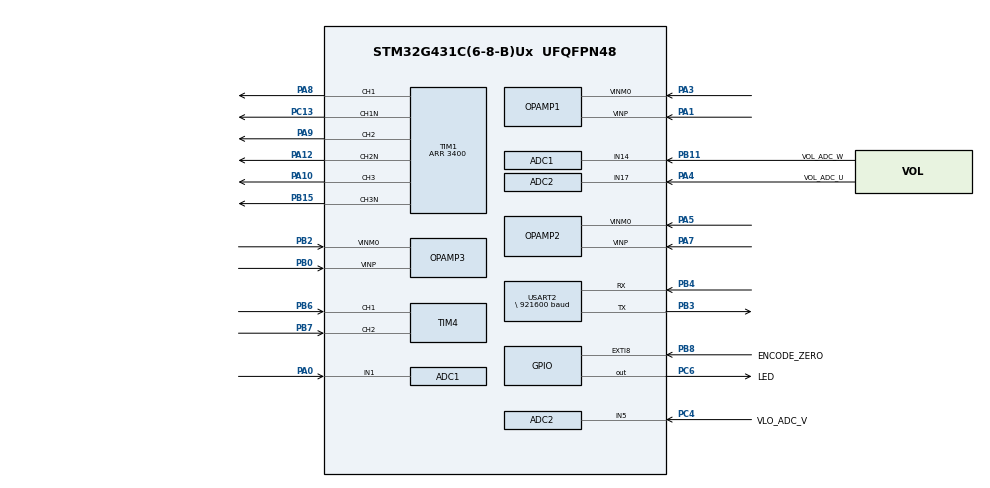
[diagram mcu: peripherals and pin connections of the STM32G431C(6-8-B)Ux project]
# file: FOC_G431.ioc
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ADC1.Channel-0\#ChannelRegularConversion=ADC_CHANNEL_VOPAMP1
ADC1.Channel-2\#ChannelRegularConversion=ADC_CHANNEL_1
ADC1.Channel-3\#ChannelRegularConversion=ADC_CHANNEL_14
ADC1.DMAAccessModeView=ENABLE
ADC1.DMAContinuousRequests=ENABLE
ADC1.EnableInjectedConversion=DISABLE
ADC1.ExternalTrigConv=ADC_EXTERNALTRIG_T1_TRGO2
ADC1.Mode=ADC_DUALMODE_REGSIMULT
ADC1.NbrOfConversion=3
ADC1.NbrOfConversionFlag=1
ADC1.OffsetNumber-0\#ChannelRegularConversion=ADC_OFFSET_NONE
ADC1.OffsetNumber-2\#ChannelRegularConversion=ADC_OFFSET_NONE
ADC1.OffsetNumber-3\#ChannelRegularConversion=ADC_OFFSET_NONE
ADC1.Rank-0\#ChannelRegularConversion=1
ADC1.Rank-2\#ChannelRegularConversion=2
ADC1.Rank-3\#ChannelRegularConversion=3
ADC1.SamplingTime-0\#ChannelRegularConversion=ADC_SAMPLETIME_12CYCLES_5
ADC1.SamplingTime-2\#ChannelRegularConversion=ADC_SAMPLETIME_12CYCLES_5
ADC1.SamplingTime-3\#ChannelRegularConversion=ADC_SAMPLETIME_12CYCLES_5
ADC1.master=1
ADC2.Channel-1\#ChannelRegularConversion=ADC_CHANNEL_VOPAMP2
ADC2.Channel-4\#ChannelRegularConversion=ADC_CHANNEL_5
ADC2.Channel-5\#ChannelRegularConversion=ADC_CHANNEL_17
ADC2.DMAAccessModeView=ENABLE
ADC2.EnableInjectedConversion=DISABLE
ADC2.Mode=ADC_DUALMODE_REGSIMULT
ADC2.NbrOfConversion=3
ADC2.NbrOfConversionFlag=1
ADC2.OffsetNumber-1\#ChannelRegularConversion=ADC_OFFSET_NONE
ADC2.OffsetNumber-4\#ChannelRegularConversion=ADC_OFFSET_NONE
ADC2.OffsetNumber-5\#ChannelRegularConversion=ADC_OFFSET_NONE
ADC2.Rank-1\#ChannelRegularConversion=1
ADC2.Rank-4\#ChannelRegularConversion=2
ADC2.Rank-5\#ChannelRegularConversion=3
ADC2.SamplingTime-1\#ChannelRegularConversion=ADC_SAMPLETIME_12CYCLES_5
ADC2.SamplingTime-4\#ChannelRegularConversion=ADC_SAMPLETIME_12CYCLES_5
ADC2.SamplingTime-5\#ChannelRegularConversion=ADC_SAMPLETIME_12CYCLES_5
Dma.ADC1.0.Direction=DMA_PERIPH_TO_MEMORY
Dma.ADC1.0.EventEnable=DISABLE
Dma.ADC1.0.Instance=DMA1_Channel1
Dma.ADC1.0.MemDataAlignment=DMA_MDATAALIGN_WORD
Dma.ADC1.0.MemInc=DMA_MINC_ENABLE
Dma.ADC1.0.Mode=DMA_CIRCULAR
Dma.ADC1.0.PeriphDataAlignment=DMA_PDATAALIGN_WORD
Dma.ADC1.0.PeriphInc=DMA_PINC_DISABLE
Dma.ADC1.0.Polarity=HAL_DMAMUX_REQ_GEN_RISING
Dma.ADC1.0.Priority=DMA_PRIORITY_HIGH
Dma.ADC1.0.RequestNumber=1
Dma.ADC1.0.SignalID=NONE
Dma.ADC1.0.SyncEnable=DISABLE
Dma.ADC1.0.SyncPolarity=HAL_DMAMUX_SYNC_NO_EVENT
Dma.ADC1.0.SyncRequestNumber=1
Dma.ADC1.0.SyncSignalID=NONE
Dma.Request0=ADC1
Dma.Request1=USART2_TX
Dma.Request2=USART2_RX
Dma.USART2_RX.2.Direction=DMA_PERIPH_TO_MEMORY
Dma.USART2_RX.2.EventEnable=DISABLE
Dma.USART2_RX.2.Instance=DMA1_Channel3
Dma.USART2_RX.2.MemDataAlignment=DMA_MDATAALIGN_BYTE
Dma.USART2_RX.2.MemInc=DMA_MINC_ENABLE
Dma.USART2_RX.2.Mode=DMA_CIRCULAR
Dma.USART2_RX.2.PeriphDataAlignment=DMA_PDATAALIGN_BYTE
Dma.USART2_RX.2.PeriphInc=DMA_PINC_DISABLE
Dma.USART2_RX.2.Polarity=HAL_DMAMUX_REQ_GEN_RISING
Dma.USART2_RX.2.Priority=DMA_PRIORITY_MEDIUM
Dma.USART2_RX.2.RequestNumber=1
Dma.USART2_RX.2.SignalID=NONE
Dma.USART2_RX.2.SyncEnable=DISABLE
Dma.USART2_RX.2.SyncPolarity=HAL_DMAMUX_SYNC_NO_EVENT
Dma.USART2_RX.2.SyncRequestNumber=1
Dma.USART2_RX.2.SyncSignalID=NONE
Dma.USART2_TX.1.Direction=DMA_MEMORY_TO_PERIPH
Dma.USART2_TX.1.EventEnable=DISABLE
Dma.USART2_TX.1.Instance=DMA1_Channel2
Dma.USART2_TX.1.MemDataAlignment=DMA_MDATAALIGN_BYTE
Dma.USART2_TX.1.MemInc=DMA_MINC_ENABLE
Dma.USART2_TX.1.Mode=DMA_NORMAL
Dma.USART2_TX.1.PeriphDataAlignment=DMA_PDATAALIGN_BYTE
Dma.USART2_TX.1.PeriphInc=DMA_PINC_DISABLE
Dma.USART2_TX.1.Polarity=HAL_DMAMUX_REQ_GEN_RISING
Dma.USART2_TX.1.Priority=DMA_PRIORITY_MEDIUM
Dma.USART2_TX.1.RequestNumber=1
Dma.USART2_TX.1.SignalID=NONE
Dma.USART2_TX.1.SyncEnable=DISABLE
Dma.USART2_TX.1.SyncPolarity=HAL_DMAMUX_SYNC_NO_EVENT
Dma.USART2_TX.1.SyncRequestNumber=1
Dma.USART2_TX.1.SyncSignalID=NONE
Mcu.Family=STM32G4
Mcu.Name=STM32G431C(6-8-B)Ux
Mcu.Package=UFQFPN48
NVIC.ADC1_2_IRQn=true\:1\:0\:true\:false\:true\:true\:true\:true
NVIC.DMA1_Channel1_IRQn=true\:0\:0\:false\:false\:true\:false\:true\:true
NVIC.DMA1_Channel2_IRQn=true\:5\:0\:true\:false\:true\:false\:true\:true
NVIC.DMA1_Channel3_IRQn=true\:5\:0\:true\:false\:true\:false\:true\:true
NVIC.FPU_IRQn=true\:0\:0\:false\:false\:true\:true\:false\:true
NVIC.PriorityGroup=NVIC_PRIORITYGROUP_4
NVIC.TIM4_IRQn=true\:0\:0\:false\:false\:true\:true\:true\:true
NVIC.USART2_IRQn=true\:5\:0\:true\:false\:true\:true\:true\:true
OPAMP1.PgaGain=OPAMP_PGA_GAIN_16_OR_MINUS_15
OPAMP2.PgaGain=OPAMP_PGA_GAIN_16_OR_MINUS_15
OPAMP3.PgaGain=OPAMP_PGA_GAIN_16_OR_MINUS_15
PA0.Mode=IN1-Single-Ended
PA0.Signal=ADC1_IN1
PA1.Mode=PGA Internally connected_IO0_BIAS
PA1.Signal=OPAMP1_VINP
PA10.Signal=S_TIM1_CH3
PA12.Mode=PWM Generation2 CH2 CH2N
PA12.Signal=TIM1_CH2N
PA3.Mode=PGA Internally connected_IO0_BIAS
PA3.Signal=OPAMP1_VINM0
PA4.GPIO_Label=VOL_ADC_U
PA4.Mode=IN17-Single-Ended
PA4.Signal=ADC2_IN17
PA5.Mode=PGA Internally connected_IO0_BIAS
PA5.Signal=OPAMP2_VINM0
PA7.Mode=PGA Internally connected_IO0_BIAS
PA7.Signal=OPAMP2_VINP
PA8.Signal=S_TIM1_CH1
PA9.Signal=S_TIM1_CH2
PB0.Mode=PGA Internally connected_IO0_BIAS
PB0.Signal=OPAMP3_VINP
PB11.GPIO_Label=VOL_ADC_W
PB11.Mode=IN14-Single-Ended
PB11.Signal=ADC1_IN14
PB15.Mode=PWM Generation3 CH3 CH3N
PB15.Signal=TIM1_CH3N
PB2.Mode=PGA Internally connected_IO0_BIAS
PB2.Signal=OPAMP3_VINM0
PB3.Mode=Asynchronous
PB3.Signal=USART2_TX
PB4.Mode=Asynchronous
PB4.Signal=USART2_RX
PB6.Signal=S_TIM4_CH1
PB7.Signal=S_TIM4_CH2
PB8-BOOT0.GPIO_Label=ENCODE_ZERO
PB8-BOOT0.GPIO_ModeDefaultEXTI=GPIO_MODE_IT_RISING
PB8-BOOT0.GPIO_PuPd=GPIO_NOPULL
PB8-BOOT0.Signal=GPXTI8
PC13.Mode=PWM Generation1 CH1 CH1N
PC13.Signal=TIM1_CH1N
PC4.GPIO_Label=VLO_ADC_V
PC4.Mode=IN5-Single-Ended
PC4.Signal=ADC2_IN5
PC6.GPIO_Label=LED
PC6.GPIO_PuPd=GPIO_PULLUP
PC6.Signal=GPIO_Output
PF0-OSC_IN.Mode=HSE-External-Oscillator
PF0-OSC_IN.Signal=RCC_OSC_IN
PF1-OSC_OUT.Mode=HSE-External-Oscillator
PF1-OSC_OUT.Signal=RCC_OSC_OUT
ProjectManager.HeapSize=0x200
ProjectManager.StackSize=0x400
ProjectManager.TargetToolchain=MDK-ARM V5.32
RCC.ADC12Freq_Value=170000000
RCC.AHBFreq_Value=170000000
RCC.APB1Freq_Value=170000000
RCC.APB1TimFreq_Value=170000000
RCC.APB2Freq_Value=170000000
RCC.APB2TimFreq_Value=170000000
RCC.CortexFreq_Value=170000000
RCC.EXTERNAL_CLOCK_VALUE=12288000
RCC.HCLKFreq_Value=170000000
RCC.HSE_VALUE=8000000
RCC.HSI48_VALUE=48000000
RCC.HSI_VALUE=16000000
RCC.LSE_VALUE=32768
RCC.PLLM=RCC_PLLM_DIV2
RCC.PLLN=85
RCC.PLLSourceVirtual=RCC_PLLSOURCE_HSE
RCC.SYSCLKFreq_VALUE=170000000
RCC.SYSCLKSource=RCC_SYSCLKSOURCE_PLLCLK
RCC.USBFreq_Value=170000000
RCC.VCOOutputFreq_Value=340000000
SH.S_TIM1_CH1.0=TIM1_CH1,PWM Generation1 CH1 CH1N
SH.S_TIM1_CH2.0=TIM1_CH2,PWM Generation2 CH2 CH2N
SH.S_TIM1_CH3.0=TIM1_CH3,PWM Generation3 CH3 CH3N
SH.S_TIM4_CH1.0=TIM4_CH1,Encoder_Interface
SH.S_TIM4_CH2.0=TIM4_CH2,Encoder_Interface
TIM1.AutoReloadPreload=TIM_AUTORELOAD_PRELOAD_ENABLE
TIM1.Break2State=TIM_BREAK2_DISABLE
TIM1.Channel-PWM\ Generation1\ CH1\ CH1N=TIM_CHANNEL_1
TIM1.Channel-PWM\ Generation2\ CH2\ CH2N=TIM_CHANNEL_2
TIM1.Channel-PWM\ Generation3\ CH3\ CH3N=TIM_CHANNEL_3
TIM1.Channel-PWM\ Generation4\ No\ Output=TIM_CHANNEL_4
TIM1.CounterMode=TIM_COUNTERMODE_CENTERALIGNED2
TIM1.DeadTime=51
TIM1.OCMode_PWM-PWM\ Generation4\ No\ Output=TIM_OCMODE_PWM2
TIM1.PeriodNoDither=3400
TIM1.PulseNoDither_4=3399
TIM1.TIM_MasterOutputTrigger2=TIM_TRGO2_OC4REF
USART2.BaudRate=\ 921600
USART2.VirtualMode-Asynchronous=VM_ASYNC
VP_ADC1_OPAMP_INTERNAL1.Mode=IN-OPAMP1
VP_ADC2_OPAMP_INTERNAL2.Mode=IN-OPAMP2
VP_ADC2_OPAMP_INTERNAL3.Mode=IN-OPAMP3
VP_SYS_VS_DBSignals.Mode=DisableDeadBatterySignals
VP_TIM1_VS_ClockSourceINT.Mode=Internal
VP_TIM1_VS_no_output4.Mode=PWM Generation4 No Output
board=custom

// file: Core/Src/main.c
/* USER CODE BEGIN Header */
/**
  ******************************************************************************
  * @file           : main.c
  * @brief          : Main program body
  ******************************************************************************
  * @attention
  *
  * Copyright (c) 2026 STMicroelectronics.
  * All rights reserved.
  *
  * This software is licensed under terms that can be found in the LICENSE file
  * in the root directory of this software component.
  * If no LICENSE file comes with this software, it is provided AS-IS.
  *
  ******************************************************************************
  */
/* USER CODE END Header */
#include "main.h"
#include "adc.h"
#include "dma.h"
#include "opamp.h"
#include "tim.h"
#include "usart.h"
#include "gpio.h"

/* USER CODE BEGIN Includes */
#include <stdio.h>

#include "../../User/setup.hpp"
#include "../../User/encoder/encoder.hpp"
/* USER CODE END Includes */

void SystemClock_Config(void);

/* USER CODE BEGIN 0 */
int fputc(int ch, FILE *f) {
    HAL_UART_Transmit(&huart2, (uint8_t *)&ch, 1, HAL_MAX_DELAY);
    return ch;
}

/* USER CODE END 0 */

int main(void)
{

  /* MCU Configuration--------------------------------------------------------*/

  /* Reset of all peripherals, Initializes the Flash interface and the Systick. */
  HAL_Init();

  /* Configure the system clock */
  SystemClock_Config();

  /* Initialize all configured peripherals */
  MX_GPIO_Init();
  MX_DMA_Init();
  MX_TIM4_Init();
  MX_USART2_UART_Init();
  MX_TIM1_Init();
  MX_ADC1_Init();
  MX_ADC2_Init();
  MX_OPAMP1_Init();
  MX_OPAMP2_Init();
  MX_OPAMP3_Init();
  /* USER CODE BEGIN 2 */
  setup();
  /* USER CODE END 2 */

  /* Infinite loop */
  while (1)
  {

  }
}

void SystemClock_Config(void)
{
  LL_FLASH_SetLatency(LL_FLASH_LATENCY_4);
  while(LL_FLASH_GetLatency() != LL_FLASH_LATENCY_4)
  {
  }
  LL_PWR_EnableRange1BoostMode();
  LL_RCC_HSE_Enable();
   /* Wait till HSE is ready */
  while(LL_RCC_HSE_IsReady() != 1)
  {
  }

  LL_RCC_PLL_ConfigDomain_SYS(LL_RCC_PLLSOURCE_HSE, LL_RCC_PLLM_DIV_2, 85, LL_RCC_PLLR_DIV_2);
  LL_RCC_PLL_EnableDomain_SYS();
  LL_RCC_PLL_Enable();
   /* Wait till PLL is ready */
  while(LL_RCC_PLL_IsReady() != 1)
  {
  }

  LL_RCC_SetSysClkSource(LL_RCC_SYS_CLKSOURCE_PLL);
  LL_RCC_SetAHBPrescaler(LL_RCC_SYSCLK_DIV_2);
   /* Wait till System clock is ready */
  while(LL_RCC_GetSysClkSource() != LL_RCC_SYS_CLKSOURCE_STATUS_PLL)
  {
  }

  /* Insure 1us transition state at intermediate medium speed clock*/
  for (__IO uint32_t i = (170 >> 1); i !=0; i--);

  /* Set AHB prescaler*/
  LL_RCC_SetAHBPrescaler(LL_RCC_SYSCLK_DIV_1);
  LL_RCC_SetAPB1Prescaler(LL_RCC_APB1_DIV_1);
  LL_RCC_SetAPB2Prescaler(LL_RCC_APB2_DIV_1);
  LL_SetSystemCoreClock(170000000);

   /* Update the time base */
  if (HAL_InitTick (TICK_INT_PRIORITY) != HAL_OK)
  {
    Error_Handler();
  }
}

void Error_Handler(void)
{
  __disable_irq();
  while (1)
  {
  }
}
